# COMP_E_356.0 register map
Vendor: Texas Instruments
Peripheral module from a debugger description file (folder MSP432).
Registers are 16-bit, read-write, no defined reset value unless marked. A register's access mark holds for its fields unless they carry their own. Offsets are as the file gives them; lines under a group give offsets from that group; [hi:lo] are bit positions; {n}, {i} and the like mark numbered series; 'fields as' and 'values as' point back to an identical list; <NAME> marks a mode.

## COMP_E
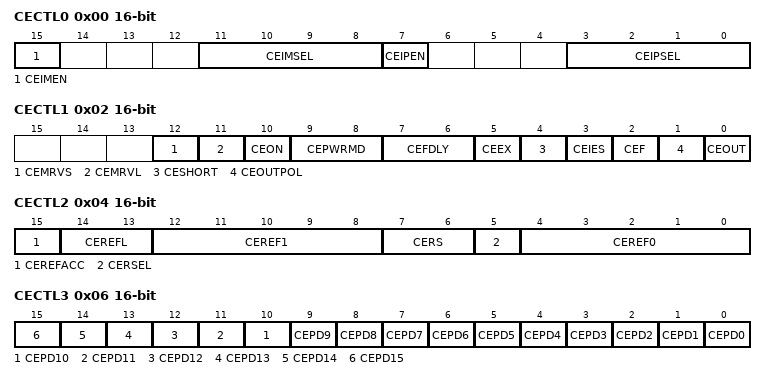
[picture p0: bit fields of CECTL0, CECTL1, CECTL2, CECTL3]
0x00 CECTL0 — Comparator Control Register 0
  [15] CEIMEN — Channel input enable for the - terminal
    0=DISABLE (Selected analog input channel for V- terminal is disabled); 1=ENABLE (Selected analog input channel for V- terminal is enabled)
  [11:8] CEIMSEL — Channel input selected for the - terminal
    {v}=Channel {v} selected (v=0..15)
  [7] CEIPEN — Channel input enable for the V+ terminal
    0=DISABLE (Selected analog input channel for V+ terminal is disabled); 1=ENABLE (Selected analog input channel for V+ terminal is enabled)
  [3:0] CEIPSEL — Channel input selected for the V+ terminal
    {v}=Channel {v} selected (v=0..15)
0x02 CECTL1 — Comparator Control Register 1
  [12] CEMRVS — This bit defines if the comparator output selects between VREF0 or VREF1 if CERS = 00, 01, or 10.
    0=Comparator output state selects between VREF0 or VREF1; 1=CEMRVL selects between VREF0 or VREF1
  [11] CEMRVL — This bit is valid of CEMRVS is set to 1
    0=VREF0 (VREF0 is selected if CERS = 00, 01, or 10); 1=VREF1 (VREF1 is selected if CERS = 00, 01, or 10)
  [10] CEON — Comparator On
    0=OFF; 1=ON
  [9:8] CEPWRMD — Power Mode
    0=High-speed mode; 1=Normal mode; 2=Ultra-low power mode
  [7:6] CEFDLY — Filter delay
    0=Typical filter delay of TBD (450) ns; 1=Typical filter delay of TBD (900) ns; 2=Typical filter delay of TBD (1800) ns; 3=Typical filter delay of TBD (3600) ns
  [5] CEEX — Exchange
  [4] CESHORT — Input short
    0=Inputs not shorted; 1=Inputs shorted
  [3] CEIES — Interrupt edge select for CEIIFG and CEIFG
    0=Rising edge for CEIFG, falling edge for CEIIFG; 1=Falling edge for CEIFG, rising edge for CEIIFG
  [2] CEF — Comparator output filter
    0=Comparator output is not filtered; 1=Comparator output is filtered
  [1] CEOUTPOL — Comparator output polarity
    0=Noninverted; 1=Inverted
  [0] CEOUT — Comparator output value
0x04 CECTL2 — Comparator Control Register 2
  [15] CEREFACC — Reference accuracy
    0=STATIC (Static mode); 1=CLOCKED (Clocked (low power, low accuracy) mode)
  [14:13] CEREFL — Reference voltage level
    0=OFF (Reference amplifier is disabled. No reference voltage is requested); 1=1P2V (1.2 V is selected as shared reference voltage input); 2=2P0V (2.0 V is selected as shared reference voltage input); 3=2P5V (2.5 V is selected as shared reference voltage input)
  [12:8] CEREF1 — Reference resistor tap 1
    {v}=Reference resistor tap for setting {v} (v=0..31)
  [7:6] CERS — Reference source
    0=No current is drawn by the reference circuitry; 1=VCC applied to the resistor ladder; 2=Shared reference voltage applied to the resistor ladder; 3=Shared reference voltage supplied to V(CREF). Resistor ladder is off
  [5] CERSEL — Reference select
    0=When CEEX = 0, VREF is applied to the V+ terminal; When CEEX = 1, VREF is applied to the V- terminal; 1=When CEEX = 0, VREF is applied to the V- terminal; When CEEX = 1, VREF is applied to the V+ terminal
  [4:0] CEREF0 — Reference resistor tap 0
    {v}=Reference resistor tap for setting {v} (v=0..31)
0x06 CECTL3 — Comparator Control Register 3
  [all] fields
    0=The input buffer is enabled; 1=The input buffer is disabled
  [n] CEPD{n} (n=0..15) — Port disable
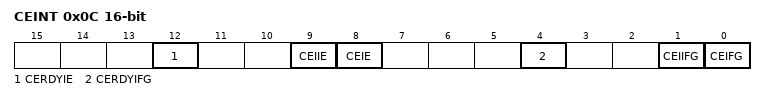
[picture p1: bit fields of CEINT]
0x0C CEINT — Comparator Interrupt Control Register
  [12] CERDYIE — Comparator ready interrupt enable
    0=DISABLE (Interrupt disabled); 1=ENABLE (Interrupt enabled)
  [9] CEIIE — Comparator output interrupt enable inverted polarity
    0=DISABLE (Interrupt disabled); 1=ENABLE (Interrupt enabled)
  [8] CEIE — Comparator output interrupt enable
    0=DISABLE (Interrupt disabled); 1=ENABLE (Interrupt enabled)
  [4] CERDYIFG — Comparator ready interrupt flag
    0=No interrupt pending; 1=Interrupt pending
  [1] CEIIFG — Comparator output inverted interrupt flag
    0=No interrupt pending; 1=Interrupt pending
  [0] CEIFG — Comparator output interrupt flag
    0=No interrupt pending; 1=Interrupt pending
0x0E CEIV ro — Comparator Interrupt Vector Word Register
  [15:0] CEIV — Comparator interrupt vector word register
    0=NONE (No interrupt pending); 2=CEIFG (Interrupt Source: CEOUT interrupt; Interrupt Flag: CEIFG; Interrupt Priority: Highest); 4=CEIIFG (Interrupt Source: CEOUT interrupt inverted polarity; Interrupt Flag: CEIIFG); 10=CERDYIFG (Interrupt Source: Comparator ready interrupt; Interrupt Flag: CERDYIFG; Interrupt Priority: Lowest)
